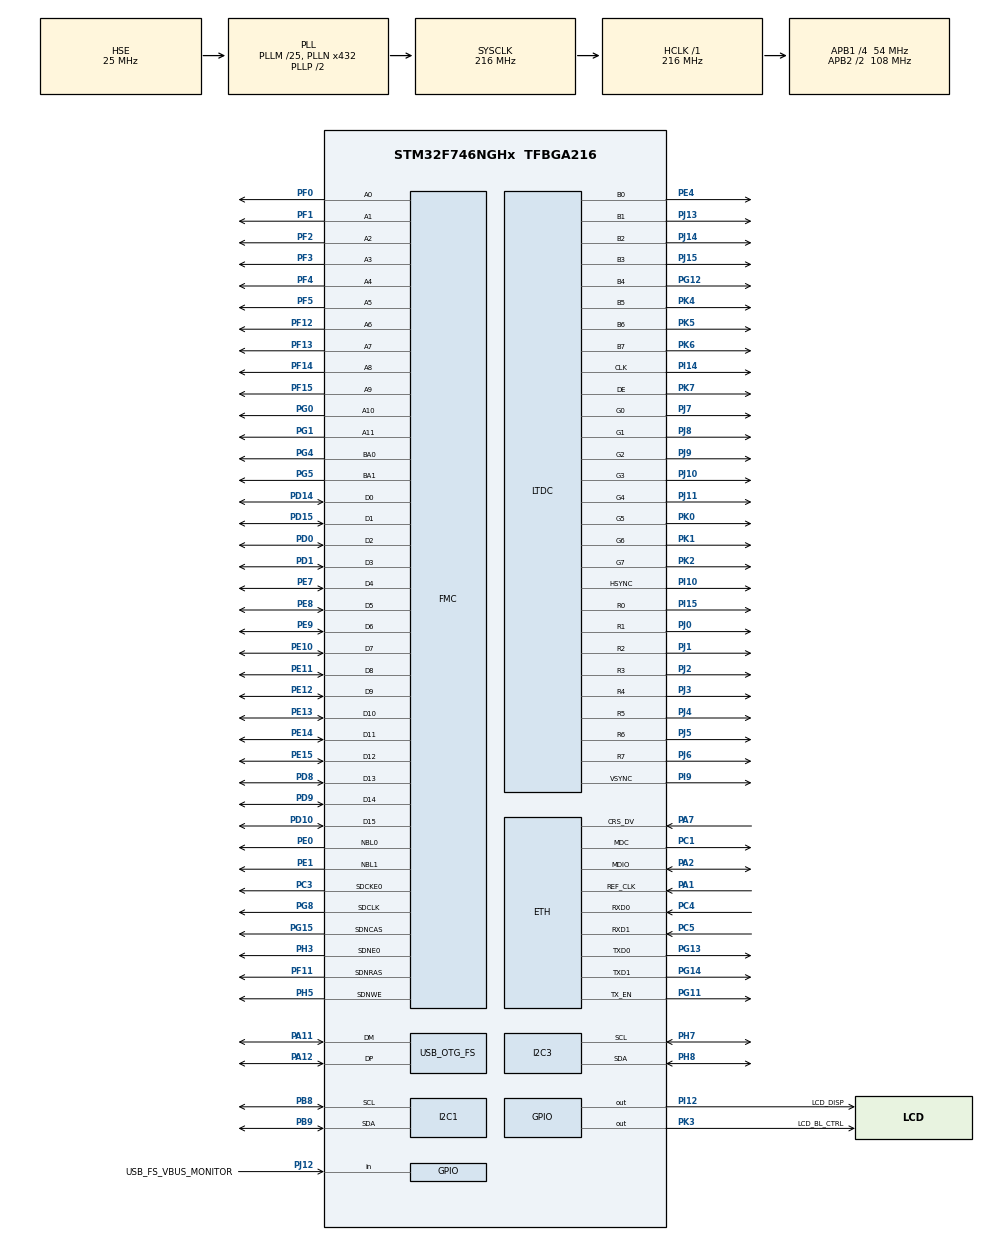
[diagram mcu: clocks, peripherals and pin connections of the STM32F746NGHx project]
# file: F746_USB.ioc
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CORTEX_M7.AccessPermission-Cortex_Memory_Protection_Unit_Region0_Settings=MPU_REGION_FULL_ACCESS
CORTEX_M7.AccessPermission-Cortex_Memory_Protection_Unit_Region1_Settings=MPU_REGION_FULL_ACCESS
CORTEX_M7.AccessPermission-Cortex_Memory_Protection_Unit_Region2_Settings=MPU_REGION_FULL_ACCESS
CORTEX_M7.BaseAddress-Cortex_Memory_Protection_Unit_Region0_Settings=0xC0000000
CORTEX_M7.BaseAddress-Cortex_Memory_Protection_Unit_Region1_Settings=0xC0000000
CORTEX_M7.BaseAddress-Cortex_Memory_Protection_Unit_Region2_Settings=0x20040000
CORTEX_M7.CPU_DCache=Enabled
CORTEX_M7.CPU_ICache=Enabled
CORTEX_M7.DisableExec-Cortex_Memory_Protection_Unit_Region0_Settings=MPU_INSTRUCTION_ACCESS_DISABLE
CORTEX_M7.DisableExec-Cortex_Memory_Protection_Unit_Region1_Settings=MPU_INSTRUCTION_ACCESS_DISABLE
CORTEX_M7.DisableExec-Cortex_Memory_Protection_Unit_Region2_Settings=MPU_INSTRUCTION_ACCESS_DISABLE
CORTEX_M7.Enable-Cortex_Memory_Protection_Unit_Region0_Settings=MPU_REGION_ENABLE
CORTEX_M7.Enable-Cortex_Memory_Protection_Unit_Region1_Settings=MPU_REGION_ENABLE
CORTEX_M7.Enable-Cortex_Memory_Protection_Unit_Region2_Settings=MPU_REGION_ENABLE
CORTEX_M7.IsBufferable-Cortex_Memory_Protection_Unit_Region0_Settings=MPU_ACCESS_BUFFERABLE
CORTEX_M7.IsBufferable-Cortex_Memory_Protection_Unit_Region1_Settings=MPU_ACCESS_NOT_BUFFERABLE
CORTEX_M7.IsBufferable-Cortex_Memory_Protection_Unit_Region2_Settings=MPU_ACCESS_NOT_BUFFERABLE
CORTEX_M7.IsCacheable-Cortex_Memory_Protection_Unit_Region0_Settings=MPU_ACCESS_CACHEABLE
CORTEX_M7.IsCacheable-Cortex_Memory_Protection_Unit_Region1_Settings=MPU_ACCESS_NOT_CACHEABLE
CORTEX_M7.IsCacheable-Cortex_Memory_Protection_Unit_Region2_Settings=MPU_ACCESS_NOT_CACHEABLE
CORTEX_M7.IsShareable-Cortex_Memory_Protection_Unit_Region0_Settings=MPU_ACCESS_NOT_SHAREABLE
CORTEX_M7.IsShareable-Cortex_Memory_Protection_Unit_Region1_Settings=MPU_ACCESS_SHAREABLE
CORTEX_M7.IsShareable-Cortex_Memory_Protection_Unit_Region2_Settings=MPU_ACCESS_SHAREABLE
CORTEX_M7.MPU_Control=MPU_PRIVILEGED_DEFAULT
CORTEX_M7.Number-Cortex_Memory_Protection_Unit_Region1_Settings=MPU_REGION_NUMBER1
CORTEX_M7.Number-Cortex_Memory_Protection_Unit_Region2_Settings=MPU_REGION_NUMBER2
CORTEX_M7.Size-Cortex_Memory_Protection_Unit_Region0_Settings=MPU_REGION_SIZE_8MB
CORTEX_M7.Size-Cortex_Memory_Protection_Unit_Region1_Settings=MPU_REGION_SIZE_512KB
CORTEX_M7.Size-Cortex_Memory_Protection_Unit_Region2_Settings=MPU_REGION_SIZE_64KB
CORTEX_M7.SubRegionDisable-Cortex_Memory_Protection_Unit_Region0_Settings=0x0
CORTEX_M7.SubRegionDisable-Cortex_Memory_Protection_Unit_Region1_Settings=0x0
CORTEX_M7.SubRegionDisable-Cortex_Memory_Protection_Unit_Region2_Settings=0x0
CORTEX_M7.TypeExtField-Cortex_Memory_Protection_Unit_Region0_Settings=MPU_TEX_LEVEL1
CORTEX_M7.TypeExtField-Cortex_Memory_Protection_Unit_Region1_Settings=MPU_TEX_LEVEL1
CORTEX_M7.TypeExtField-Cortex_Memory_Protection_Unit_Region2_Settings=MPU_TEX_LEVEL1
ETH.MediaInterface=HAL_ETH_RMII_MODE
FMC.CASLatency1=FMC_SDRAM_CAS_LATENCY_2
FMC.ExitSelfRefreshDelay1=8
FMC.LoadToActiveDelay1=2
FMC.RCDDelay1=2
FMC.RPDelay1=2
FMC.ReadBurst1=FMC_SDRAM_RBURST_ENABLE
FMC.RowCycleDelay1=7
FMC.SDClockPeriod1=FMC_SDRAM_CLOCK_PERIOD_2
FMC.SelfRefreshTime1=5
FMC.WriteRecoveryTime1=3
I2C1.Timing=0x20404768
I2C3.Timing=0x20404768
LTDC.ActiveH=272
LTDC.ActiveW=480
LTDC.Alpha_L0=255
LTDC.BlendingFactor1_L0=LTDC_BLENDING_FACTOR1_CA
LTDC.BlendingFactor2_L0=LTDC_BLENDING_FACTOR2_CA
LTDC.FBStartAdress_L0=0xC0000000
LTDC.HBP=13
LTDC.HFP=32
LTDC.HSync=41
LTDC.ImageHeight_L0=272
LTDC.ImageWidth_L0=480
LTDC.Layers=0
LTDC.PixelFormat_L0=LTDC_PIXEL_FORMAT_RGB565
LTDC.VBP=2
LTDC.VFP=2
LTDC.VSync=10
LTDC.WindowX1_L0=480
LTDC.WindowY1_L0=272
Mcu.Family=STM32F7
Mcu.Name=STM32F746NGHx
Mcu.Package=TFBGA216
NVIC.DMA2D_IRQn=true\:7\:0\:false\:false\:true\:true\:true\:true\:true
NVIC.ETH_IRQn=true\:6\:0\:false\:false\:true\:true\:true\:true\:true
NVIC.LTDC_IRQn=true\:7\:0\:false\:false\:true\:true\:true\:true\:true
NVIC.OTG_FS_IRQn=true\:6\:0\:false\:false\:true\:true\:true\:true\:true
NVIC.PriorityGroup=NVIC_PRIORITYGROUP_4
NVIC.TIM6_DAC_IRQn=true\:15\:0\:false\:false\:true\:false\:false\:true\:true
NVIC.TimeBase=TIM6_DAC_IRQn
NVIC.TimeBaseIP=TIM6
PA1.Mode=RMII
PA1.Signal=ETH_REF_CLK
PA11.Mode=Device_Only
PA11.Signal=USB_OTG_FS_DM
PA12.Mode=Device_Only
PA12.Signal=USB_OTG_FS_DP
PA13.Mode=Serial_Wire
PA13.Signal=SYS_JTMS-SWDIO
PA14.Mode=Serial_Wire
PA14.Signal=SYS_JTCK-SWCLK
PA2.Mode=RMII
PA2.Signal=ETH_MDIO
PA7.Mode=RMII
PA7.Signal=ETH_CRS_DV
PJ12.GPIO_Label=USB_FS_VBUS_MONITOR
PJ12.Signal=GPIO_Input
PC1.Mode=RMII
PC1.Signal=ETH_MDC
PC3.Mode=SdramChipSelect1_1
PC3.Signal=FMC_SDCKE0
PC4.Mode=RMII
PC4.Signal=ETH_RXD0
PC5.Mode=RMII
PC5.Signal=ETH_RXD1
PD0.Signal=FMC_D2_DA2
PD1.Signal=FMC_D3_DA3
PD10.Signal=FMC_D15_DA15
PD14.Signal=FMC_D0_DA0
PD15.Signal=FMC_D1_DA1
PD8.Signal=FMC_D13_DA13
PD9.Signal=FMC_D14_DA14
PE0.Signal=FMC_NBL0
PE1.Signal=FMC_NBL1
PE10.Signal=FMC_D7_DA7
PE11.Signal=FMC_D8_DA8
PE12.Signal=FMC_D9_DA9
PE13.Signal=FMC_D10_DA10
PE14.Signal=FMC_D11_DA11
PE15.Signal=FMC_D12_DA12
PE4.Mode=RGB888
PE4.Signal=LTDC_B0
PE7.Signal=FMC_D4_DA4
PE8.Signal=FMC_D5_DA5
PE9.Signal=FMC_D6_DA6
PF0.Signal=FMC_A0
PF1.Signal=FMC_A1
PF11.Signal=FMC_SDNRAS
PF12.Signal=FMC_A6
PF13.Signal=FMC_A7
PF14.Signal=FMC_A8
PF15.Signal=FMC_A9
PF2.Signal=FMC_A2
PF3.Signal=FMC_A3
PF4.Signal=FMC_A4
PF5.Signal=FMC_A5
PG0.Signal=FMC_A10
PG1.Signal=FMC_A11
PG11.Mode=RMII
PG11.Signal=ETH_TX_EN
PG12.Mode=RGB888
PG12.Signal=LTDC_B4
PG13.Mode=RMII
PG13.Signal=ETH_TXD0
PG14.Mode=RMII
PG14.Signal=ETH_TXD1
PG15.Signal=FMC_SDNCAS
PG4.Signal=FMC_A14_BA0
PG5.Signal=FMC_A15_BA1
PG8.Signal=FMC_SDCLK
PH0/OSC_IN.Mode=HSE-External-Oscillator
PH0/OSC_IN.Signal=RCC_OSC_IN
PH1/OSC_OUT.Mode=HSE-External-Oscillator
PH1/OSC_OUT.Signal=RCC_OSC_OUT
PH3.Mode=SdramChipSelect1_1
PH3.Signal=FMC_SDNE0
PH5.Signal=FMC_SDNWE
PH7.Mode=I2C
PH7.Signal=I2C3_SCL
PH8.Mode=I2C
PH8.Signal=I2C3_SDA
PB8.Mode=I2C
PB8.Signal=I2C1_SCL
PB9.Mode=I2C
PB9.Signal=I2C1_SDA
PI10.Mode=RGB888
PI10.Signal=LTDC_HSYNC
PI12.GPIO_Label=LCD_DISP
PI12.Signal=GPIO_Output
PI14.Mode=RGB888
PI14.Signal=LTDC_CLK
PI15.Mode=RGB888
PI15.Signal=LTDC_R0
PI9.Mode=RGB888
PI9.Signal=LTDC_VSYNC
PJ0.Mode=RGB888
PJ0.Signal=LTDC_R1
PJ1.Mode=RGB888
PJ1.Signal=LTDC_R2
PJ10.Mode=RGB888
PJ10.Signal=LTDC_G3
PJ11.Mode=RGB888
PJ11.Signal=LTDC_G4
PJ13.Mode=RGB888
PJ13.Signal=LTDC_B1
PJ14.Mode=RGB888
PJ14.Signal=LTDC_B2
PJ15.Mode=RGB888
PJ15.Signal=LTDC_B3
PJ2.Mode=RGB888
PJ2.Signal=LTDC_R3
PJ3.Mode=RGB888
PJ3.Signal=LTDC_R4
PJ4.Mode=RGB888
PJ4.Signal=LTDC_R5
PJ5.Mode=RGB888
PJ5.Signal=LTDC_R6
PJ6.Mode=RGB888
PJ6.Signal=LTDC_R7
PJ7.Mode=RGB888
PJ7.Signal=LTDC_G0
PJ8.Mode=RGB888
PJ8.Signal=LTDC_G1
PJ9.Mode=RGB888
PJ9.Signal=LTDC_G2
PK0.Mode=RGB888
PK0.Signal=LTDC_G5
PK1.Mode=RGB888
PK1.Signal=LTDC_G6
PK2.Mode=RGB888
PK2.Signal=LTDC_G7
PK3.GPIO_Label=LCD_BL_CTRL
PK3.Signal=GPIO_Output
PK4.Mode=RGB888
PK4.Signal=LTDC_B5
PK5.Mode=RGB888
PK5.Signal=LTDC_B6
PK6.Mode=RGB888
PK6.Signal=LTDC_B7
PK7.Mode=RGB888
PK7.Signal=LTDC_DE
ProjectManager.HeapSize=0x200
ProjectManager.StackSize=0x400
ProjectManager.TargetToolchain=STM32CubeIDE
RCC.AHBFreq_Value=216000000
RCC.APB1CLKDivider=RCC_HCLK_DIV4
RCC.APB1Freq_Value=54000000
RCC.APB1TimFreq_Value=108000000
RCC.APB2CLKDivider=RCC_HCLK_DIV2
RCC.APB2Freq_Value=108000000
RCC.APB2TimFreq_Value=216000000
RCC.CortexFreq_Value=216000000
RCC.HCLKFreq_Value=216000000
RCC.HSE_VALUE=25000000
RCC.HSI_VALUE=16000000
RCC.LSE_VALUE=32768
RCC.PLLM=25
RCC.PLLN=432
RCC.PLLQ=9
RCC.PLLSAIN=192
RCC.PLLSAIR=5
RCC.PLLSAIRDiv=RCC_PLLSAIDIVR_4
RCC.SYSCLKFreq_VALUE=216000000
RCC.SYSCLKSource=RCC_SYSCLKSOURCE_PLLCLK
RCC.USBFreq_Value=48000000
RCC.VCOOutputFreq_Value=432000000
SH.FMC_A0.0=FMC_A0,12b-sda1
SH.FMC_A1.0=FMC_A1,12b-sda1
SH.FMC_A10.0=FMC_A10,12b-sda1
SH.FMC_A11.0=FMC_A11,12b-sda1
SH.FMC_A14_BA0.0=FMC_BA0,FourSdramBanks1
SH.FMC_A15_BA1.0=FMC_BA1,FourSdramBanks1
SH.FMC_A2.0=FMC_A2,12b-sda1
SH.FMC_A3.0=FMC_A3,12b-sda1
SH.FMC_A4.0=FMC_A4,12b-sda1
SH.FMC_A5.0=FMC_A5,12b-sda1
SH.FMC_A6.0=FMC_A6,12b-sda1
SH.FMC_A7.0=FMC_A7,12b-sda1
SH.FMC_A8.0=FMC_A8,12b-sda1
SH.FMC_A9.0=FMC_A9,12b-sda1
SH.FMC_D0_DA0.0=FMC_D0,sd-16b-d1
SH.FMC_D10_DA10.0=FMC_D10,sd-16b-d1
SH.FMC_D11_DA11.0=FMC_D11,sd-16b-d1
SH.FMC_D12_DA12.0=FMC_D12,sd-16b-d1
SH.FMC_D13_DA13.0=FMC_D13,sd-16b-d1
SH.FMC_D14_DA14.0=FMC_D14,sd-16b-d1
SH.FMC_D15_DA15.0=FMC_D15,sd-16b-d1
SH.FMC_D1_DA1.0=FMC_D1,sd-16b-d1
SH.FMC_D2_DA2.0=FMC_D2,sd-16b-d1
SH.FMC_D3_DA3.0=FMC_D3,sd-16b-d1
SH.FMC_D4_DA4.0=FMC_D4,sd-16b-d1
SH.FMC_D5_DA5.0=FMC_D5,sd-16b-d1
SH.FMC_D6_DA6.0=FMC_D6,sd-16b-d1
SH.FMC_D7_DA7.0=FMC_D7,sd-16b-d1
SH.FMC_D8_DA8.0=FMC_D8,sd-16b-d1
SH.FMC_D9_DA9.0=FMC_D9,sd-16b-d1
SH.FMC_NBL0.0=FMC_NBL0,Sd2ByteEnable1
SH.FMC_NBL1.0=FMC_NBL1,Sd2ByteEnable1
SH.FMC_SDCLK.0=FMC_SDCLK,12b-sda1
SH.FMC_SDNCAS.0=FMC_SDNCAS,12b-sda1
SH.FMC_SDNRAS.0=FMC_SDNRAS,12b-sda1
SH.FMC_SDNWE.0=FMC_SDNWE,12b-sda1
STMicroelectronics.X-CUBE-AZRTOS-F7.1.1.0.InterfacesCcNetworkJjEthernetOoInterface=true
STMicroelectronics.X-CUBE-AZRTOS-F7.1.1.0.InterfacesCcNetworkJjEthernetOoPhyOoInterface=LAN8742IiPhyIiInterface
STMicroelectronics.X-CUBE-AZRTOS-F7.1.1.0.NetXDuoCcNetworkJjNetXDuoJjAddonsOoDHCPOoClient=true
STMicroelectronics.X-CUBE-AZRTOS-F7.1.1.0.NetXDuoCcNetworkJjNetXDuoJjNXOoCore=true
STMicroelectronics.X-CUBE-AZRTOS-F7.1.1.0.STM32CubeIiBSPIiComponentsCcBoardOoPartJjETHPhyJjLAN8742=true
STMicroelectronics.X-CUBE-AZRTOS-F7.1.1.0.ThreadXCcRTOSJjThreadXJjCore=true
STMicroelectronics.X-CUBE-AZRTOS-F7.1.1.0.USBXCcUSBJjUSBXJjCoreSystem=true
STMicroelectronics.X-CUBE-AZRTOS-F7.1.1.0.USBXCcUSBJjUSBXJjUXOoDeviceOoControllers=true
STMicroelectronics.X-CUBE-AZRTOS-F7.1.1.0.USBXCcUSBJjUSBXJjUXOoDeviceOoCoreStack=true
STMicroelectronics.X-CUBE-AZRTOS-F7.1.1.0.USBXCcUSBJjUSBXJjUXOoHostOoClassOoASIX=false
STMicroelectronics.X-CUBE-AZRTOS-F7.1.1.0.USBXCcUSBJjUSBXJjUXOoHostOoClassOoAUDIO=false
STMicroelectronics.X-CUBE-AZRTOS-F7.1.1.0.USBXCcUSBJjUSBXJjUXOoHostOoClassOoCDCOoACM=false
STMicroelectronics.X-CUBE-AZRTOS-F7.1.1.0.USBXCcUSBJjUSBXJjUXOoHostOoClassOoCDCOoECM=false
STMicroelectronics.X-CUBE-AZRTOS-F7.1.1.0.USBXCcUSBJjUSBXJjUXOoHostOoClassOoGSER=false
STMicroelectronics.X-CUBE-AZRTOS-F7.1.1.0.USBXCcUSBJjUSBXJjUXOoHostOoClassOoHIDOoCore=false
STMicroelectronics.X-CUBE-AZRTOS-F7.1.1.0.USBXCcUSBJjUSBXJjUXOoHostOoClassOoHIDOoKeyboard=false
STMicroelectronics.X-CUBE-AZRTOS-F7.1.1.0.USBXCcUSBJjUSBXJjUXOoHostOoClassOoHIDOoMouse=false
STMicroelectronics.X-CUBE-AZRTOS-F7.1.1.0.USBXCcUSBJjUSBXJjUXOoHostOoClassOoHIDOoRCU=false
STMicroelectronics.X-CUBE-AZRTOS-F7.1.1.0.USBXCcUSBJjUSBXJjUXOoHostOoClassOoPIMA=false
STMicroelectronics.X-CUBE-AZRTOS-F7.1.1.0.USBXCcUSBJjUSBXJjUXOoHostOoClassOoPRINTER=false
STMicroelectronics.X-CUBE-AZRTOS-F7.1.1.0.USBXCcUSBJjUSBXJjUXOoHostOoClassOoPROLIFIC=false
STMicroelectronics.X-CUBE-AZRTOS-F7.1.1.0.USBXCcUSBJjUSBXJjUXOoHostOoClassOoSTORAGE=false
STMicroelectronics.X-CUBE-AZRTOS-F7.1.1.0.USBXCcUSBJjUSBXJjUXOoHostOoClassOoSWAR=false
STMicroelectronics.X-CUBE-AZRTOS-F7.1.1.0.USBXCcUSBJjUSBXJjUXOoHostOoClassOoVIDEO=false
STMicroelectronics.X-CUBE-AZRTOS-F7.1.1.0_IsAnAzureRtosMw=true
USB_OTG_FS.VirtualMode=Device_Only
VP_DMA2D_VS_DMA2D.Mode=DMA2D_Activate
VP_STMicroelectronics.X-CUBE-AZRTOS-F7_VS_BoardOoPartJjSTM32CubeIiBSPIiComponents_1.1.0_1.1.0.Mode=BoardOoPartJjSTM32CubeIiBSPIiComponents
VP_STMicroelectronics.X-CUBE-AZRTOS-F7_VS_NetworkJjInterfaces_2.1.0_1.1.0.Mode=NetworkJjInterfaces
VP_STMicroelectronics.X-CUBE-AZRTOS-F7_VS_NetworkJjNetXDuo_6.1.10_1.1.0.Mode=NetworkJjNetXDuo
VP_STMicroelectronics.X-CUBE-AZRTOS-F7_VS_RTOSJjThreadX_6.1.10_1.1.0.Mode=RTOSJjThreadX
VP_STMicroelectronics.X-CUBE-AZRTOS-F7_VS_USBJjUSBX_6.1.10_1.1.0.Mode=USBJjUSBX
VP_SYS_VS_tim6.Mode=TIM6
board=STM32F746G-DISCO

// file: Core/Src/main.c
/* USER CODE BEGIN Header */
/**
  ******************************************************************************
  * @file           : main.c
  * @brief          : Main program body
  ******************************************************************************
  * @attention
  *
  * Copyright (c) 2026 STMicroelectronics.
  * All rights reserved.
  *
  * This software is licensed under terms that can be found in the LICENSE file
  * in the root directory of this software component.
  * If no LICENSE file comes with this software, it is provided AS-IS.
  *
  ******************************************************************************
  */
/* USER CODE END Header */
#include "app_threadx.h"
#include "main.h"
#include "dma2d.h"
#include "eth.h"
#include "i2c.h"
#include "ltdc.h"
#include "usb_otg.h"
#include "gpio.h"
#include "fmc.h"

/* USER CODE BEGIN Includes */

#include "debug_log.h"

/* USER CODE END Includes */

void SystemClock_Config(void);
static void MPU_Config(void);
/* USER CODE BEGIN PFP */

static uint32_t SDRAM_SelfTest(void);
static void LCD_ShowStartupPattern(void);

/* USER CODE END PFP */

/* USER CODE BEGIN 0 */

#define LCD_FRAMEBUFFER_ADDRESS          0xC0000000UL
#define SDRAM_TEST_ADDRESS               0xC007F000UL
#define LCD_WIDTH                        480U
#define LCD_HEIGHT                       272U

static uint32_t SDRAM_SelfTest(void)
{
  static const uint32_t patterns[] =
  {
    0x00000000UL, 0xFFFFFFFFUL, 0xAAAAAAAAUL, 0x55555555UL,
    0x12345678UL, 0x87654321UL, 0xA5A55A5AUL, 0x5A5AA5A5UL
  };
  volatile uint32_t *memory = (volatile uint32_t *)SDRAM_TEST_ADDRESS;
  uint32_t index;
  uint32_t expected;

  for (index = 0U; index < 64U; index++)
  {
    memory[index] = patterns[index % (sizeof(patterns) / sizeof(patterns[0]))] ^
                    (index * 0x01010101UL);
  }
  __DSB();

  for (index = 0U; index < 64U; index++)
  {
    expected = patterns[index % (sizeof(patterns) / sizeof(patterns[0]))] ^
               (index * 0x01010101UL);
    if (memory[index] != expected)
    {
      Debug_Log_Hex("[SDRAM] failed address: ",
                    SDRAM_TEST_ADDRESS + (index * sizeof(uint32_t)));
      Debug_Log_Hex("[SDRAM] expected: ", expected);
      Debug_Log_Hex("[SDRAM] read:     ", memory[index]);
      return 1U;
    }
  }

  for (index = 0U; index < 64U; index++)
  {
    memory[index] = 0U;
  }
  __DSB();
  Debug_Log_Line("[SDRAM] test passed");
  return 0U;
}

static void LCD_ShowStartupPattern(void)
{
  volatile uint16_t *framebuffer =
      (volatile uint16_t *)LCD_FRAMEBUFFER_ADDRESS;
  HAL_StatusTypeDef address_status;
  HAL_StatusTypeDef reload_status;
  uint32_t x;
  uint32_t y;
  uint16_t color;

  for (y = 0U; y < LCD_HEIGHT; y++)
  {
    for (x = 0U; x < LCD_WIDTH; x++)
    {
      if (x < (LCD_WIDTH / 4U))
      {
        color = 0xF800U; /* Red. */
      }
      else if (x < (LCD_WIDTH / 2U))
      {
        color = 0x07E0U; /* Green. */
      }
      else if (x < ((LCD_WIDTH * 3U) / 4U))
      {
        color = 0x001FU; /* Blue. */
      }
      else
      {
        color = 0xFFFFU; /* White. */
      }
      framebuffer[(y * LCD_WIDTH) + x] = color;
    }
  }
  __DSB();

  address_status = HAL_LTDC_SetAddress(&hltdc, LCD_FRAMEBUFFER_ADDRESS, 0U);
  reload_status = HAL_LTDC_Reload(&hltdc, LTDC_RELOAD_IMMEDIATE);
  HAL_GPIO_WritePin(LCD_DISP_GPIO_Port, LCD_DISP_Pin, GPIO_PIN_SET);
  HAL_Delay(10U);
  HAL_GPIO_WritePin(LCD_BL_CTRL_GPIO_Port, LCD_BL_CTRL_Pin, GPIO_PIN_SET);

  Debug_Log_U32("[LCD] HAL_LTDC_SetAddress: ", (uint32_t)address_status);
  Debug_Log_U32("[LCD] HAL_LTDC_Reload:     ", (uint32_t)reload_status);
  Debug_Log_Hex("[LCD] LTDC GCR:  ", LTDC->GCR);
  Debug_Log_Hex("[LCD] Layer CFBAR: ", LTDC_Layer1->CFBAR);
  Debug_Log_Hex("[LCD] GPIOI ODR: ", GPIOI->ODR);
  Debug_Log_Hex("[LCD] GPIOK ODR: ", GPIOK->ODR);
  Debug_Log_Line("[LCD] startup color bars enabled");
  Debug_Log_Line("[LCD] holding hardware test for 2 seconds");
  HAL_Delay(2000U);
}

/* USER CODE END 0 */

int main(void)
{

  /* MPU Configuration--------------------------------------------------------*/
  MPU_Config();

  /* Enable the CPU Cache */

  /* Enable I-Cache---------------------------------------------------------*/
  SCB_EnableICache();

  /* Enable D-Cache---------------------------------------------------------*/
  SCB_EnableDCache();

  /* MCU Configuration--------------------------------------------------------*/

  /* Reset of all peripherals, Initializes the Flash interface and the Systick. */
  HAL_Init();

  /* Configure the system clock */
  SystemClock_Config();

  /* USER CODE BEGIN SysInit */

  Debug_Log_Init();
  Debug_Log_SetStage("system clock configured");

  /* USER CODE END SysInit */

  /* Initialize all configured peripherals */
  Debug_Log_SetStage("GPIO init");
  MX_GPIO_Init();
  Debug_Log_SetStage("DMA2D init");
  MX_DMA2D_Init();
  Debug_Log_SetStage("FMC/SDRAM init");
  MX_FMC_Init();
  if (SDRAM_SelfTest() != 0U)
  {
    Debug_Log_SetStage("SDRAM self-test failed");
    Error_Handler();
  }
  Debug_Log_SetStage("I2C1/BME280 bus init");
  MX_I2C1_Init();
  Debug_Log_SetStage("I2C3/touch init");
  MX_I2C3_Init();
  Debug_Log_SetStage("LTDC init");
  MX_LTDC_Init();
  /* USER CODE BEGIN 2 */

  LCD_ShowStartupPattern();

  /* Ethernet initialization does not wait for a cable or an IP address. */
  Debug_Log_SetStage("Ethernet MAC init (cable optional)");
  MX_ETH_Init();

  /* USBX initializes and starts the PCD only after its descriptors and
     vendor class are registered. */

  Debug_Log_SetStage("enter ThreadX kernel");

  /* USER CODE END 2 */

  MX_ThreadX_Init();

  /* We should never get here as control is now taken by the scheduler */

  /* Infinite loop */
  while (1)
  {

  }
}

void SystemClock_Config(void)
{
  RCC_OscInitTypeDef RCC_OscInitStruct = {0};
  RCC_ClkInitTypeDef RCC_ClkInitStruct = {0};

  /** Configure the main internal regulator output voltage
  */
  __HAL_RCC_PWR_CLK_ENABLE();
  __HAL_PWR_VOLTAGESCALING_CONFIG(PWR_REGULATOR_VOLTAGE_SCALE1);

  /** Initializes the RCC Oscillators according to the specified parameters
  * in the RCC_OscInitTypeDef structure.
  */
  RCC_OscInitStruct.OscillatorType = RCC_OSCILLATORTYPE_HSE;
  RCC_OscInitStruct.HSEState = RCC_HSE_ON;
  RCC_OscInitStruct.PLL.PLLState = RCC_PLL_ON;
  RCC_OscInitStruct.PLL.PLLSource = RCC_PLLSOURCE_HSE;
  RCC_OscInitStruct.PLL.PLLM = 25;
  RCC_OscInitStruct.PLL.PLLN = 432;
  RCC_OscInitStruct.PLL.PLLP = RCC_PLLP_DIV2;
  RCC_OscInitStruct.PLL.PLLQ = 9;
  if (HAL_RCC_OscConfig(&RCC_OscInitStruct) != HAL_OK)
  {
    Error_Handler();
  }

  /** Activate the Over-Drive mode
  */
  if (HAL_PWREx_EnableOverDrive() != HAL_OK)
  {
    Error_Handler();
  }

  /** Initializes the CPU, AHB and APB buses clocks
  */
  RCC_ClkInitStruct.ClockType = RCC_CLOCKTYPE_HCLK|RCC_CLOCKTYPE_SYSCLK
                              |RCC_CLOCKTYPE_PCLK1|RCC_CLOCKTYPE_PCLK2;
  RCC_ClkInitStruct.SYSCLKSource = RCC_SYSCLKSOURCE_PLLCLK;
  RCC_ClkInitStruct.AHBCLKDivider = RCC_SYSCLK_DIV1;
  RCC_ClkInitStruct.APB1CLKDivider = RCC_HCLK_DIV4;
  RCC_ClkInitStruct.APB2CLKDivider = RCC_HCLK_DIV2;

  if (HAL_RCC_ClockConfig(&RCC_ClkInitStruct, FLASH_LATENCY_7) != HAL_OK)
  {
    Error_Handler();
  }
}

 /* MPU Configuration */

void MPU_Config(void)
{
  MPU_Region_InitTypeDef MPU_InitStruct = {0};

  /* Disables the MPU */
  HAL_MPU_Disable();

  /** Initializes and configures the Region and the memory to be protected
  */
  MPU_InitStruct.Enable = MPU_REGION_ENABLE;
  MPU_InitStruct.Number = MPU_REGION_NUMBER0;
  MPU_InitStruct.BaseAddress = 0xC0000000;
  MPU_InitStruct.Size = MPU_REGION_SIZE_8MB;
  MPU_InitStruct.SubRegionDisable = 0x0;
  MPU_InitStruct.TypeExtField = MPU_TEX_LEVEL1;
  MPU_InitStruct.AccessPermission = MPU_REGION_FULL_ACCESS;
  MPU_InitStruct.DisableExec = MPU_INSTRUCTION_ACCESS_DISABLE;
  MPU_InitStruct.IsShareable = MPU_ACCESS_NOT_SHAREABLE;
  MPU_InitStruct.IsCacheable = MPU_ACCESS_CACHEABLE;
  MPU_InitStruct.IsBufferable = MPU_ACCESS_BUFFERABLE;

  HAL_MPU_ConfigRegion(&MPU_InitStruct);

  /** Initializes and configures the Region and the memory to be protected
  */
  MPU_InitStruct.Number = MPU_REGION_NUMBER1;
  MPU_InitStruct.Size = MPU_REGION_SIZE_512KB;
  MPU_InitStruct.IsShareable = MPU_ACCESS_SHAREABLE;
  MPU_InitStruct.IsCacheable = MPU_ACCESS_NOT_CACHEABLE;
  MPU_InitStruct.IsBufferable = MPU_ACCESS_NOT_BUFFERABLE;

  HAL_MPU_ConfigRegion(&MPU_InitStruct);

  /** Initializes and configures the Region and the memory to be protected
  */
  MPU_InitStruct.Number = MPU_REGION_NUMBER2;
  MPU_InitStruct.BaseAddress = 0x20040000;
  MPU_InitStruct.Size = MPU_REGION_SIZE_64KB;

  HAL_MPU_ConfigRegion(&MPU_InitStruct);
  /* Enables the MPU */
  HAL_MPU_Enable(MPU_PRIVILEGED_DEFAULT);

}

void HAL_TIM_PeriodElapsedCallback(TIM_HandleTypeDef *htim)
{
  if (htim->Instance == TIM6)
  {
    HAL_IncTick();
  }
}

void Error_Handler(void)
{
  /* USER CODE BEGIN Error_Handler_Debug */
  /* User can add his own implementation to report the HAL error return state */
  /* HAL error callbacks can fire from interrupt context, and this path is
     about to halt with interrupts disabled either way, so it deliberately
     uses the raw, unlocked Debug_Log_Write() instead of Debug_Log_Line():
     taking the debug log mutex here could be illegal (ISR) or deadlock on
     a lock a just-interrupted thread still owns. */
  Debug_Log_Write("*** Error_Handler ***\n");
  Debug_Log_Write("last stage: ");
  Debug_Log_Write(Debug_Log_GetStage());
  Debug_Log_Write("\n");
  __disable_irq();
  while (1)
  {
  }
  /* USER CODE END Error_Handler_Debug */
}
